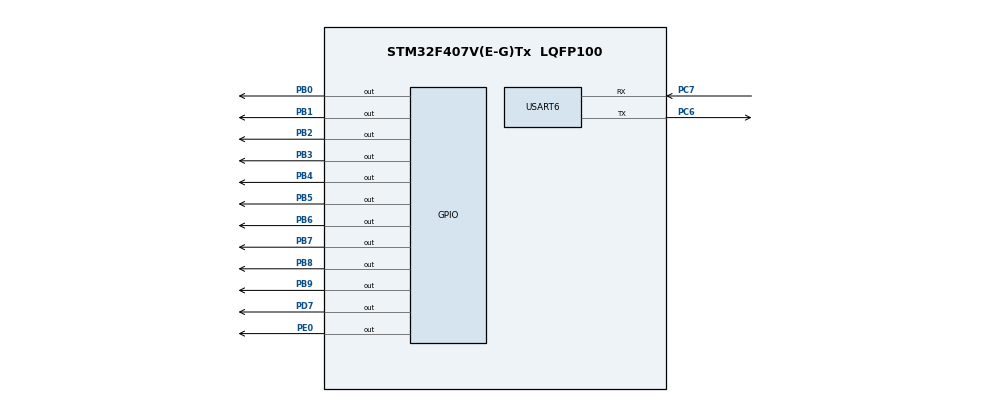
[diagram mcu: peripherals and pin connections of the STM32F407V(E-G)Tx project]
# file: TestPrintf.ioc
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Mcu.Family=STM32F4
Mcu.Name=STM32F407V(E-G)Tx
Mcu.Package=LQFP100
NVIC.PriorityGroup=NVIC_PRIORITYGROUP_0
NVIC.USART6_IRQn=true\:0\:0
PB0.Signal=GPIO_Output
PB1.Signal=GPIO_Output
PB2.Signal=GPIO_Output
PB3.Signal=GPIO_Output
PB4.Signal=GPIO_Output
PB5.Signal=GPIO_Output
PB6.Signal=GPIO_Output
PB7.Signal=GPIO_Output
PB8.Signal=GPIO_Output
PB9.Signal=GPIO_Output
PC6.Mode=Asynchronous
PC6.Signal=USART6_TX
PC7.Mode=Asynchronous
PC7.Signal=USART6_RX
PD7.Signal=GPIO_Output
PE0.Signal=GPIO_Output
PH0-OSC_IN.Mode=HSE-External-Oscillator
PH0-OSC_IN.Signal=RCC_OSC_IN
PH1-OSC_OUT.Mode=HSE-External-Oscillator
PH1-OSC_OUT.Signal=RCC_OSC_OUT
ProjectManager.TargetToolchain=MDK-ARM 4.73
RCC.APB1CLKDivider=RCC_HCLK_DIV4
RCC.APB2CLKDivider=RCC_HCLK_DIV2
RCC.HSE_VALUE=25000000
RCC.HSI_VALUE=16000000
RCC.LSE_VALUE=32768
RCC.PLLM=25
RCC.PLLN=336
RCC.PLLSource=RCC_PLLSOURCE_HSE
RCC.SYSCLKSource=RCC_SYSCLKSOURCE_PLLCLK

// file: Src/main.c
/**
  ******************************************************************************
  * File Name          : main.c
  * Date               : 14/05/2014 11:48:30
  * Description        : Main program body
  ******************************************************************************
  *
  * COPYRIGHT(c) 2014 STMicroelectronics
  *
  * Redistribution and use in source and binary forms, with or without modification,
  * are permitted provided that the following conditions are met:
  *   1. Redistributions of source code must retain the above copyright notice,
  *      this list of conditions and the following disclaimer.
  *   2. Redistributions in binary form must reproduce the above copyright notice,
  *      this list of conditions and the following disclaimer in the documentation
  *      and/or other materials provided with the distribution.
  *   3. Neither the name of STMicroelectronics nor the names of its contributors
  *      may be used to endorse or promote products derived from this software
  *      without specific prior written permission.
  *
  * THIS SOFTWARE IS PROVIDED BY THE COPYRIGHT HOLDERS AND CONTRIBUTORS "AS IS"
  * AND ANY EXPRESS OR IMPLIED WARRANTIES, INCLUDING, BUT NOT LIMITED TO, THE
  * IMPLIED WARRANTIES OF MERCHANTABILITY AND FITNESS FOR A PARTICULAR PURPOSE ARE
  * DISCLAIMED. IN NO EVENT SHALL THE COPYRIGHT HOLDER OR CONTRIBUTORS BE LIABLE
  * FOR ANY DIRECT, INDIRECT, INCIDENTAL, SPECIAL, EXEMPLARY, OR CONSEQUENTIAL
  * DAMAGES (INCLUDING, BUT NOT LIMITED TO, PROCUREMENT OF SUBSTITUTE GOODS OR
  * SERVICES; LOSS OF USE, DATA, OR PROFITS; OR BUSINESS INTERRUPTION) HOWEVER
  * CAUSED AND ON ANY THEORY OF LIABILITY, WHETHER IN CONTRACT, STRICT LIABILITY,
  * OR TORT (INCLUDING NEGLIGENCE OR OTHERWISE) ARISING IN ANY WAY OUT OF THE USE
  * OF THIS SOFTWARE, EVEN IF ADVISED OF THE POSSIBILITY OF SUCH DAMAGE.
  *
  ******************************************************************************
  */

#include "stm32f4xx_hal.h"
#include<stdio.h>
#include "hal_debug.h"
#include "flip_buff.h"
#include "string.h"

//UART_HandleTypeDef huart6;

USER_UART_HandleTypeDef HalUartHandle6;

uint8_t userbuffer[64];

static void SystemClock_Config(void);
static void MX_GPIO_Init(void);
static void MX_USART6_UART_Init(void);

int main(void)
{

	uint8_t ReadCount = 0;

  /* MCU Configuration----------------------------------------------------------*/

  /* Reset of all peripherals, Initializes the Flash interface and the Systick. */
  HAL_Init();

  /* Configure the system clock */
  SystemClock_Config();
	UartInit();
  /* Initialize all configured peripherals */
  MX_GPIO_Init();
  MX_USART6_UART_Init();
	printf("init ....\r\n");

	//HAL_UART_Receive_IT(&(HalUartHandle6.UartHandle), userbuffer, 10);
	HAL_UART_Open(&HalUartHandle6, userbuffer, 1);   //parameter

	/************for test the structure data*******************************************************/
//	HalUartHandle6.UartHandle.RxXferCount = 10 - 8;
//	HalUartHandle6.UartHandle.pRxBuffPtr += 8;
	//HalUartHandle6.UpBufferCount = 8;
	//HalUartHandle6.UpBufferPtr +=8;
	/******************************************************************/

  /* USER CODE BEGIN 3 */
  /* Infinite loop */
  while (1)
  {
	//			HAL_Delay(100);
				ReadCount = HAL_UART_Read(&HalUartHandle6, userbuffer, 20);
				if(ReadCount)
				{
						printf("%s", userbuffer);
						memset(userbuffer, 0, ReadCount);
				}

  }
  /* USER CODE END 3 */

}

/** System Clock Configuration
*/
static void SystemClock_Config(void)
{

  RCC_ClkInitTypeDef RCC_ClkInitStruct;
  RCC_OscInitTypeDef RCC_OscInitStruct;

  __PWR_CLK_ENABLE();

  __HAL_PWR_VOLTAGESCALING_CONFIG(PWR_REGULATOR_VOLTAGE_SCALE1);

  RCC_OscInitStruct.OscillatorType = RCC_OSCILLATORTYPE_HSE;
  RCC_OscInitStruct.HSEState = RCC_HSE_ON;
  RCC_OscInitStruct.PLL.PLLState = RCC_PLL_ON;
  RCC_OscInitStruct.PLL.PLLSource = RCC_PLLSOURCE_HSE;
  RCC_OscInitStruct.PLL.PLLM = 25;
  RCC_OscInitStruct.PLL.PLLN = 336;
  RCC_OscInitStruct.PLL.PLLP = RCC_PLLP_DIV2;
  RCC_OscInitStruct.PLL.PLLQ = 4;
  HAL_RCC_OscConfig(&RCC_OscInitStruct);

  RCC_ClkInitStruct.ClockType = RCC_CLOCKTYPE_SYSCLK|RCC_CLOCKTYPE_PCLK1
                              |RCC_CLOCKTYPE_PCLK2;
  RCC_ClkInitStruct.SYSCLKSource = RCC_SYSCLKSOURCE_PLLCLK;
  RCC_ClkInitStruct.AHBCLKDivider = RCC_SYSCLK_DIV1;
  RCC_ClkInitStruct.APB1CLKDivider = RCC_HCLK_DIV4;
  RCC_ClkInitStruct.APB2CLKDivider = RCC_HCLK_DIV2;
  HAL_RCC_ClockConfig(&RCC_ClkInitStruct, FLASH_LATENCY_5);

}

/* USART6 init function */
void MX_USART6_UART_Init(void)
{

  HalUartHandle6.UartHandle.Instance = USART6;
  HalUartHandle6.UartHandle.Init.BaudRate = 115200;
  HalUartHandle6.UartHandle.Init.WordLength = UART_WORDLENGTH_8B;
  HalUartHandle6.UartHandle.Init.StopBits = UART_STOPBITS_1;
  HalUartHandle6.UartHandle.Init.Parity = UART_PARITY_NONE;
  HalUartHandle6.UartHandle.Init.Mode = UART_MODE_TX_RX;
  HalUartHandle6.UartHandle.Init.HwFlowCtl = UART_HWCONTROL_NONE;
  HalUartHandle6.UartHandle.Init.OverSampling = UART_OVERSAMPLING_16;
  HAL_UART_Init(&(HalUartHandle6.UartHandle));

}

/** Configure pins as
        * Analog
        * Input
        * Output
        * EVENT_OUT
        * EXTI
*/
void MX_GPIO_Init(void)
{

  GPIO_InitTypeDef GPIO_InitStruct;

  /* GPIO Ports Clock Enable */
  __GPIOH_CLK_ENABLE();
  __GPIOB_CLK_ENABLE();
  __GPIOC_CLK_ENABLE();
  __GPIOD_CLK_ENABLE();
  __GPIOE_CLK_ENABLE();

  /*Configure GPIO pins : PB0 PB1 PB2 PB3
                           PB4 PB5 PB6 PB7
                           PB8 PB9 */
  GPIO_InitStruct.Pin = GPIO_PIN_0|GPIO_PIN_1|GPIO_PIN_2|GPIO_PIN_3
                          |GPIO_PIN_4|GPIO_PIN_5|GPIO_PIN_6|GPIO_PIN_7
                          |GPIO_PIN_8|GPIO_PIN_9;
  GPIO_InitStruct.Pull = GPIO_NOPULL;
  GPIO_InitStruct.Speed = GPIO_SPEED_LOW;
  HAL_GPIO_Init(GPIOB, &GPIO_InitStruct);

  /*Configure GPIO pin : PD7 */
  GPIO_InitStruct.Pin = GPIO_PIN_7;
  GPIO_InitStruct.Pull = GPIO_NOPULL;
  GPIO_InitStruct.Speed = GPIO_SPEED_LOW;
  HAL_GPIO_Init(GPIOD, &GPIO_InitStruct);

  /*Configure GPIO pin : PE0 */
  GPIO_InitStruct.Pin = GPIO_PIN_0;
  GPIO_InitStruct.Pull = GPIO_NOPULL;
  GPIO_InitStruct.Speed = GPIO_SPEED_LOW;
  HAL_GPIO_Init(GPIOE, &GPIO_InitStruct);

}

void HAL_UART_RxCpltCallback(UART_HandleTypeDef *UartHandle)
{

	printf("low buffer overflow\r\n");    ///  if this fuction was called , the uart can't work continue.i can't understand why does it can not work contnue after i call Hal_UART_Open();
	HAL_UART_Open(&HalUartHandle6, userbuffer, 1);

}

/************************ (C) COPYRIGHT STMicroelectronics *****END OF FILE****/
